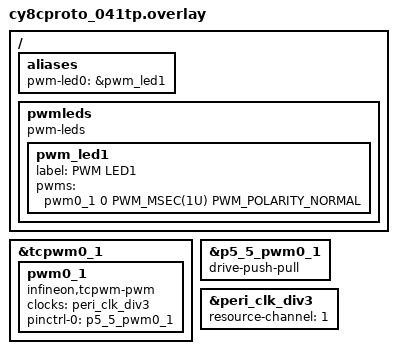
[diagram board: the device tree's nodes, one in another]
/*
 * Copyright (c) 2025 Infineon Technologies AG,
 * or an affiliate of Infineon Technologies AG.
 *
 * SPDX-License-Identifier: Apache-2.0
 */

#include <zephyr/dt-bindings/pwm/pwm.h>

/ {
	aliases {
		pwm-led0 = &pwm_led1;
	};

	pwmleds {
		compatible = "pwm-leds";

		pwm_led1: pwm_led1 {
			label = "PWM LED1";
			pwms = <&pwm0_1 0 PWM_MSEC(1U) PWM_POLARITY_NORMAL>;
		};
	};
};

&tcpwm0_1 {
	status = "okay";

	pwm0_1 {
		clocks = <&peri_clk_div3>;
		compatible = "infineon,tcpwm-pwm";
		status = "okay";
		pinctrl-0 = <&p5_5_pwm0_1>;
		pinctrl-names = "default";
	};
};

&p5_5_pwm0_1 {
	drive-push-pull;
};

&peri_clk_div3 {
	status = "okay";
	resource-channel = <1>;
};
